# SF32LB52x register map
File version: 1.0
CPU: CM33 r0p1, little endian, MPU, FPU, 3 interrupt priority bits
Registers are 32-bit, read-write, reset 0x0 unless marked. A register's access mark holds for its fields unless they carry their own. Offsets are from the block's base; [hi:lo] are bit positions; {n}, {i} and the like mark numbered series; 'fields as' and 'values as' point back to an identical list.

## HPSYS_PINMUX
Base 0x50003000
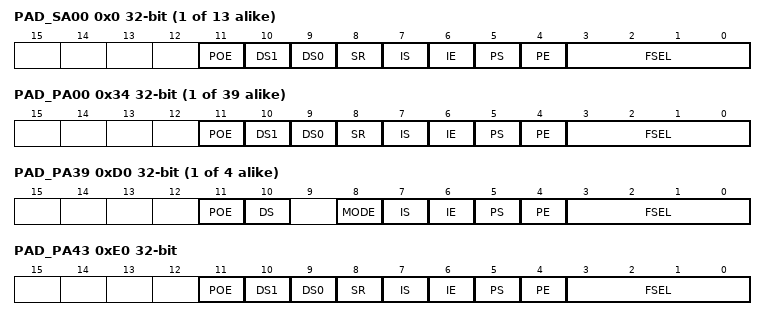
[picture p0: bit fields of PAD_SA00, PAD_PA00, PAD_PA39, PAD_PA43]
{0x0+4i} PAD_SA{i:02} (i=0..12)
  [11] POE — Reserved. Always set to logic LOW
  [10] DS1 — Drive Select 1. Used to select output drive strength
  [9] DS0 — Drive Select 0. Used to select output drive strength
  [8] SR — Slew Rate. Logic HIGH selects slow slew rate, logic LOW selects fast slew rate
  [7] IS — Input Select. Logic LOW selects CMOS input, logic HIGH selects Schmitt input
  [6] IE — Input Enable. Logic HIGH enables the input buffer
  [5] PS — Pull Select. Logic HIGH selects pull-up, logic LOW select pull-down
  [4] PE — Pull Enable. Logic HIGH enables week pull device
  [3:0] FSEL — Function Select
{0x34+4i} PAD_PA{i:02} (i=0..38)
  fields as PAD_SA00
{0x34+4i} PAD_PA{i} (i=39..42)
  [11] POE — Reserved. Always set to logic LOW
  [10] DS — Drive Select. Logic LOW selects 4mA drive,logic HIGH selects 20mA drive
  [8] MODE — Mode Select. Logic LOW enables GPIO mode,logic HIGH enables I2C mode
  [7] IS — Input Select. Logic LOW selects CMOS input, logic HIGH selects Schmitt input
  [6] IE — Input Enable. Logic HIGH enables the input buffer
  [5] PS — Pull Select. Logic HIGH selects pull-up, logic LOW select pull-down
  [4] PE — Pull Enable. Logic HIGH enables week pull device
  [3:0] FSEL — Function Select
0xE0 PAD_PA43
  fields as PAD_SA00
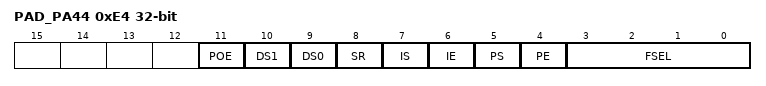
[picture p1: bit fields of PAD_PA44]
0xE4 PAD_PA44
  fields as PAD_SA00

## EFUSEC — efuse control
Base 0x5000C000
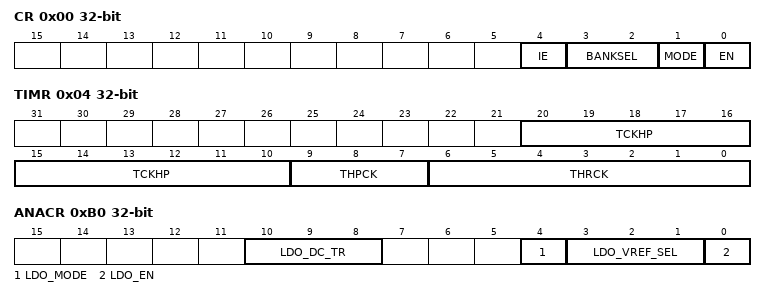
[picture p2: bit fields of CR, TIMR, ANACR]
0x00 CR — Control Register
  [4] IE — Interrupt enable
  [3:2] BANKSEL — Bank select
  [1] MODE — 0 - READ, 1 - PGM
  [0] EN — Write 1 to enable PGM/READ. Self clear
0x04 TIMR — Timer Register
  [20:10] TCKHP — SCLK high period for PGM. Recommended value ~10us
  [9:7] THPCK — SCLK to CSB hold time into PGM mode. Recommended value > 20ns
  [6:0] THRCK — SCLK to CSB hold time into READ mode. Recmmended value > 500ns
0x08 SR — Status Register
  [0] DONE — Indicates PGM/READ done. Write 1 to clear
{0x10+4i} PGM_DATA{i} (i=0..7) — Program Data{i}
  [31:0] DATA
{0x30+4i} BANK0_DATA{i} (i=0..7)
  [31:0] DATA
{0x50+4i} BANK1_DATA{i} (i=0..7)
  [31:0] DATA
{0x70+4i} BANK2_DATA{i} (i=0..7)
  [31:0] DATA
{0x90+4i} BANK3_DATA{i} (i=0..7)
  [31:0] DATA
0xB0 ANACR — Bank3 Data7
  [10:8] LDO_DC_TR, [4] LDO_MODE, [3:1] LDO_VREF_SEL, [0] LDO_EN
0xB4 DB_SEL — debug signal select

## AES
Base 0x5000D000
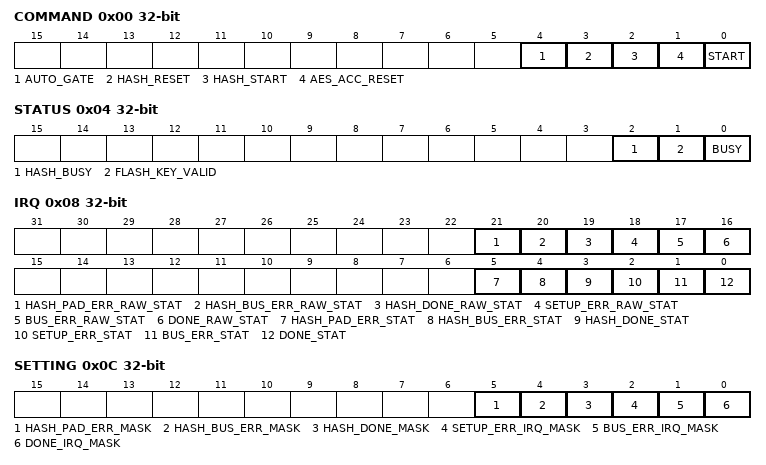
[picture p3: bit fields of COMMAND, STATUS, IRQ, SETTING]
0x00 COMMAND
  [4] AUTO_GATE — auto clock gating
  [3] HASH_RESET — HASH_ACC soft reset, 1'h1: reset the HASH_ACC block
  [2] HASH_START — write 1 to trigger the HASH_ACC block
  [1] AES_ACC_RESET — AES_ACC soft reset, 1'h1: reset the AES_ACC block
  [0] START — write 1 to trigger the AES_ACC block
0x04 STATUS
  [2] HASH_BUSY — HASH_ACC block is busy
  [1] FLASH_KEY_VALID — flash key valid indicator
  [0] BUSY — AES_ACC block is busy
0x08 IRQ
  [21] HASH_PAD_ERR_RAW_STAT — HASH_ACC padding error raw status
  [20] HASH_BUS_ERR_RAW_STAT — HASH_ACC bus error raw status
  [19] HASH_DONE_RAW_STAT — HASH_ACC done raw status
  [18] SETUP_ERR_RAW_STAT — AES_ACC setup error raw status
  [17] BUS_ERR_RAW_STAT — AES_ACC bus error raw status
  [16] DONE_RAW_STAT — AES_ACC done raw status
  [5] HASH_PAD_ERR_STAT — HASH_ACC padding error status
  [4] HASH_BUS_ERR_STAT — HASH_ACC bus error status
  [3] HASH_DONE_STAT — HASH_ACC done status
  [2] SETUP_ERR_STAT — AES_ACC setup error status
  [1] BUS_ERR_STAT — AES_ACC bus error status
  [0] DONE_STAT — AES_ACC done status
0x0C SETTING
  [5] HASH_PAD_ERR_MASK — HASH_ACC padding error interrupt mask, 0: mask the interrupt
  [4] HASH_BUS_ERR_MASK — HASH_ACC bus error interrpt mask, 0: mask the interrupt
  [3] HASH_DONE_MASK — HASH_ACC done interrupt mask, 0: mask the interrupt
  [2] SETUP_ERR_IRQ_MASK — AES_ACC setup error interrupt mask, 0: mask the interrupt
  [1] BUS_ERR_IRQ_MASK — AES_ACC bus error interrupt mask, 0: mask the interrupt
  [0] DONE_IRQ_MASK — AES_ACC done interrupt mask, 0: mask the interrupt
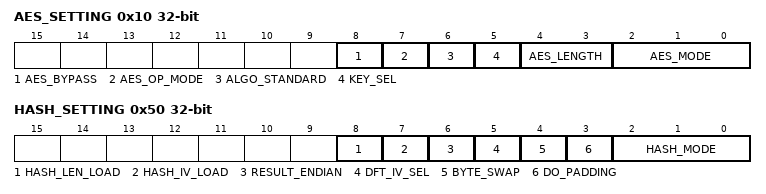
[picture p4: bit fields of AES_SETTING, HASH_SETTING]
0x10 AES_SETTING
  [8] AES_BYPASS — 1'h0: normal operation 1'h1: bypass
  [7] AES_OP_MODE — 1'h0: decryption 1'h1: encryption
  [6] ALGO_STANDARD — 1'h0: AES 1'h1: SM4
  [5] KEY_SEL — 1'h0: select key from AES_ACC key registers 1'h1: use internal root key
  [4:3] AES_LENGTH — AES Length: 2'h0: 128-bit 2'h1: 192-bit 2'h2: 256-bit 2'h3: Reserved
  [2:0] AES_MODE — AES Mode: 3'h0: ECB 3'h1: CTR 3'h2: CBC Others: Reserved
0x14 DMA_IN
  [31:0] ADDR — AES_ACC input data address
0x18 DMA_OUT
  [31:0] ADDR — AES_ACC output data address
0x1C DMA_DATA
  [27:0] SIZE — AES_ACC data block size, AES_ACC only support block aligned transaction. Each block contains 16 bytes.
{0x20+4i} IV_W{i} (i=0..2) — Initial Vector Word {i}
  [31:0] DATA — Initial Vector Word
0x2C IV_W3 — Initial Vector Word3
  [31:0] DATA — Initial Vector Word
{0x30+4i} EXT_KEY_W{i} (i=0..7) — External Key Word{i}
  [31:0] DATA — External Key Word
0x50 HASH_SETTING
  [8] HASH_LEN_LOAD — write 1 to load hash length
  [7] HASH_IV_LOAD — write 1 to load hash iv
  [6] RESULT_ENDIAN — hash result endian setting: 1'h0: little endian 1'h1: big endian
  [5] DFT_IV_SEL — HASH default iv select. 1'h0: default iv according to hash mode 1'h1: default iv from HASH_IV_H* registers
  [4] BYTE_SWAP — HASH byte swap option. Set 1 to swap byte order when read data from memory.
  [3] DO_PADDING — HASH padding enable. Set 1 to do padding after data transfer.
  [2:0] HASH_MODE — HASH Mode: 3'h0: SHA-1 3'h1: SHA-224 3'h2: SHA-256 3'h3: SM3 Others: Reserved
0x54 HASH_DMA_IN
  [31:0] ADDR — input data address
0x58 HASH_DMA_DATA
  [31:0] SIZE — HASH input data byte size.
{0x5C+4i} HASH_IV_H{i} (i=0..7)
  [31:0] DATA — HASH IV H
{0x7C+4i} HASH_RESULT_H{i} (i=0..7)
  [31:0] DATA — HASH result
0x9C HASH_LEN_L — HASH load length l
  [31:0] DATA
0xA0 HASH_LEN_H — HASH load length h
  [28:0] DATA
0xA4 HASH_RESULT_LEN_L — HASH result length l
  [31:0] DATA
0xA8 HASH_RESULT_LEN_H — HASH result length h
  [28:0] DATA
